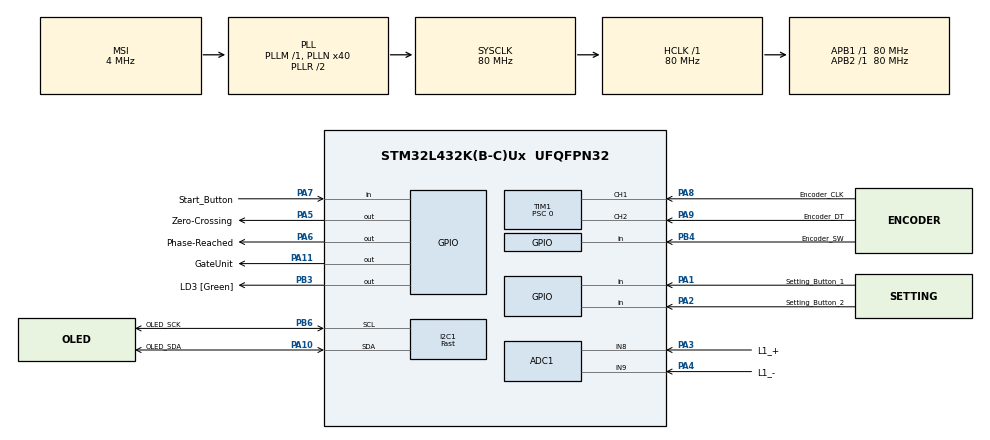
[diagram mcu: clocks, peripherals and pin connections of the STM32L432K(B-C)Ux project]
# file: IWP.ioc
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ADC1.Channel-1\#ChannelRegularConversion=ADC_CHANNEL_8
ADC1.NbrOfConversion=1
ADC1.NbrOfConversionFlag=1
ADC1.OffsetNumber-1\#ChannelRegularConversion=ADC_OFFSET_NONE
ADC1.Rank-1\#ChannelRegularConversion=1
ADC1.SamplingTime-1\#ChannelRegularConversion=ADC_SAMPLETIME_640CYCLES_5
ADC1.SingleDiff-1\#ChannelRegularConversion=ADC_DIFFERENTIAL_ENDED
ADC1.master=1
I2C1.I2C_Speed_Mode=I2C_Fast
I2C1.Timing=0x00702991
Mcu.Family=STM32L4
Mcu.Name=STM32L432K(B-C)Ux
Mcu.Package=UFQFPN32
NVIC.ADC1_IRQn=true\:0\:0\:false\:false\:true\:true\:true\:true
NVIC.PriorityGroup=NVIC_PRIORITYGROUP_4
NVIC.TIM2_IRQn=true\:0\:0\:false\:false\:true\:true\:true\:true
PA0.GPIO_Label=MCO [High speed clock in]
PA0.Mode=HSE-External-Clock-Source-for-LittleOrca
PA0.Signal=RCC_CK_IN
PA1.GPIO_Label=Setting_Button_1
PA1.GPIO_PuPd=GPIO_PULLDOWN
PA1.Signal=GPIO_Input
PA10.GPIO_Label=OLED_SDA
PA10.Mode=I2C
PA10.Signal=I2C1_SDA
PA11.GPIO_Label=GateUnit
PA11.Signal=GPIO_Output
PA13\ (JTMS-SWDIO).GPIO_Label=SWDIO
PA13\ (JTMS-SWDIO).Mode=Serial_Wire
PA13\ (JTMS-SWDIO).Signal=SYS_JTMS-SWDIO
PA14\ (JTCK-SWCLK).GPIO_Label=SWCLK
PA14\ (JTCK-SWCLK).Mode=Serial_Wire
PA14\ (JTCK-SWCLK).Signal=SYS_JTCK-SWCLK
PA2.GPIO_Label=Setting_Button_2
PA2.GPIO_PuPd=GPIO_PULLDOWN
PA2.Signal=GPIO_Input
PA3.GPIO_Label=L1_+
PA3.Signal=ADCx_IN8
PA4.GPIO_Label=L1_-
PA4.Signal=ADCx_IN9
PA5.GPIO_Label=Zero-Crossing
PA5.Signal=GPIO_Output
PA6.GPIO_Label=Phase-Reached
PA6.Signal=GPIO_Output
PA7.GPIO_Label=Start_Button
PA7.GPIO_PuPd=GPIO_PULLDOWN
PA7.Signal=GPIO_Input
PA8.GPIO_Label=Encoder_CLK
PA8.Signal=S_TIM1_CH1
PA9.GPIO_Label=Encoder_DT
PA9.Signal=S_TIM1_CH2
PB3\ (JTDO-TRACESWO).GPIO_Label=LD3 [Green]
PB3\ (JTDO-TRACESWO).Signal=GPIO_Output
PB4\ (NJTRST).GPIO_Label=Encoder_SW
PB4\ (NJTRST).GPIO_PuPd=GPIO_PULLDOWN
PB4\ (NJTRST).Signal=GPIO_Input
PB6.GPIO_Label=OLED_SCK
PB6.Mode=I2C
PB6.Signal=I2C1_SCL
PC14-OSC32_IN\ (PC14).Mode=LSE-External-Oscillator
PC14-OSC32_IN\ (PC14).Signal=RCC_OSC32_IN
PC15-OSC32_OUT\ (PC15).Mode=LSE-External-Oscillator
PC15-OSC32_OUT\ (PC15).Signal=RCC_OSC32_OUT
ProjectManager.HeapSize=0x200
ProjectManager.StackSize=0x400
ProjectManager.TargetToolchain=STM32CubeIDE
RCC.ADCFreq_Value=32000000
RCC.AHBFreq_Value=80000000
RCC.APB1Freq_Value=80000000
RCC.APB1TimFreq_Value=80000000
RCC.APB2Freq_Value=80000000
RCC.APB2TimFreq_Value=80000000
RCC.CortexFreq_Value=80000000
RCC.HCLKFreq_Value=80000000
RCC.HSE_VALUE=8000000
RCC.HSI16_VALUE=16000000
RCC.HSI48_VALUE=48000000
RCC.HSI_VALUE=16000000
RCC.MSI_VALUE=4000000
RCC.PLLMUL=RCC_PLLMUL_4
RCC.PLLN=40
RCC.PLLSAI1N=16
RCC.SYSCLKFreq_VALUE=80000000
RCC.SYSCLKSource=RCC_SYSCLKSOURCE_PLLCLK
RCC.USBFreq_Value=32000000
RCC.VCOOutputFreq_Value=160000000
SH.ADCx_IN8.0=ADC1_IN8,IN8-Differential
SH.ADCx_IN9.0=ADC1_IN9,IN8-Differential
SH.S_TIM1_CH1.0=TIM1_CH1,Encoder_Interface
SH.S_TIM1_CH2.0=TIM1_CH2,Encoder_Interface
TIM1.AutoReloadPreload=TIM_AUTORELOAD_PRELOAD_ENABLE
TIM1.EncoderMode=TIM_ENCODERMODE_TI12
TIM1.IC1Filter=10
TIM1.IC1Polarity=TIM_ICPOLARITY_FALLING
TIM1.IC2Filter=10
TIM1.IC2Polarity=TIM_ICPOLARITY_FALLING
TIM1.Period=65535
TIM1.Prescaler=0
TIM2.Channel-Output\ Compare1\ No\ Output=TIM_CHANNEL_1
TIM2.Period=2000 - 1
TIM2.Prescaler=20 - 1
TIM6.Prescaler=80 - 1
TIM6.TIM_MasterOutputTrigger=TIM_TRGO_RESET
VP_TIM2_VS_no_output1.Mode=Output Compare1 No Output
VP_TIM6_VS_ClockSourceINT.Mode=Enable_Timer
board=NUCLEO-L432KC

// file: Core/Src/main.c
/* USER CODE BEGIN Header */
/**
 ******************************************************************************
 * @file           : main.c
 * @brief          : Main program body
 ******************************************************************************
 * @attention
 *
 * Copyright (c) 2024 STMicroelectronics.
 * All rights reserved.
 *
 * This software is licensed under terms that can be found in the LICENSE file
 * in the root directory of this software component.
 * If no LICENSE file comes with this software, it is provided AS-IS.
 *
 ******************************************************************************
 */
/* USER CODE END Header */
#include "main.h"
#include "adc.h"
#include "i2c.h"
#include "tim.h"
#include "gpio.h"

/* USER CODE BEGIN Includes */
#include "PLL/PLL.h"
/* USER CODE END Includes */

void SystemClock_Config(void);

/* USER CODE BEGIN 0 */
extern void runTest();
/* USER CODE END 0 */

int main(void) {

	/* MCU Configuration--------------------------------------------------------*/

	/* Reset of all peripherals, Initializes the Flash interface and the Systick. */
	HAL_Init();

	/* USER CODE BEGIN Init */
	/* Initialize model */

	/* USER CODE END Init */

	/* Configure the system clock */
	SystemClock_Config();

	/* Initialize all configured peripherals */
	MX_GPIO_Init();
	MX_I2C1_Init();
	MX_TIM1_Init();
	MX_TIM2_Init();
	MX_ADC1_Init();
	MX_TIM6_Init();
	/* USER CODE BEGIN 2 */
	// Initializes the PLL
	PLL_initialize();

	// Starts the first ADC-Conversion
	HAL_ADC_Start_IT(&hadc1);

	// Starts the ISR for Timer 2
	HAL_TIM_Base_Start_IT(&htim2);

	// Starts the Timr 6 for the delay_us() function
	HAL_TIM_Base_Start(&htim6);

	// executes Tests for the Application
	runTest();

	/* USER CODE END 2 */

	/* Infinite loop */
	while (1) {

	}
}

void SystemClock_Config(void) {
	RCC_OscInitTypeDef RCC_OscInitStruct = { 0 };
	RCC_ClkInitTypeDef RCC_ClkInitStruct = { 0 };

	/** Configure the main internal regulator output voltage
	 */
	if (HAL_PWREx_ControlVoltageScaling(PWR_REGULATOR_VOLTAGE_SCALE1)
			!= HAL_OK) {
		Error_Handler();
	}

	/** Configure LSE Drive Capability
	 */
	HAL_PWR_EnableBkUpAccess();
	__HAL_RCC_LSEDRIVE_CONFIG(RCC_LSEDRIVE_LOW);

	/** Initializes the RCC Oscillators according to the specified parameters
	 * in the RCC_OscInitTypeDef structure.
	 */
	RCC_OscInitStruct.OscillatorType = RCC_OSCILLATORTYPE_LSE
			| RCC_OSCILLATORTYPE_MSI;
	RCC_OscInitStruct.LSEState = RCC_LSE_ON;
	RCC_OscInitStruct.MSIState = RCC_MSI_ON;
	RCC_OscInitStruct.MSICalibrationValue = 0;
	RCC_OscInitStruct.MSIClockRange = RCC_MSIRANGE_6;
	RCC_OscInitStruct.PLL.PLLState = RCC_PLL_ON;
	RCC_OscInitStruct.PLL.PLLSource = RCC_PLLSOURCE_MSI;
	RCC_OscInitStruct.PLL.PLLM = 1;
	RCC_OscInitStruct.PLL.PLLN = 40;
	RCC_OscInitStruct.PLL.PLLP = RCC_PLLP_DIV7;
	RCC_OscInitStruct.PLL.PLLQ = RCC_PLLQ_DIV2;
	RCC_OscInitStruct.PLL.PLLR = RCC_PLLR_DIV2;
	if (HAL_RCC_OscConfig(&RCC_OscInitStruct) != HAL_OK) {
		Error_Handler();
	}

	/** Initializes the CPU, AHB and APB buses clocks
	 */
	RCC_ClkInitStruct.ClockType = RCC_CLOCKTYPE_HCLK | RCC_CLOCKTYPE_SYSCLK
			| RCC_CLOCKTYPE_PCLK1 | RCC_CLOCKTYPE_PCLK2;
	RCC_ClkInitStruct.SYSCLKSource = RCC_SYSCLKSOURCE_PLLCLK;
	RCC_ClkInitStruct.AHBCLKDivider = RCC_SYSCLK_DIV1;
	RCC_ClkInitStruct.APB1CLKDivider = RCC_HCLK_DIV1;
	RCC_ClkInitStruct.APB2CLKDivider = RCC_HCLK_DIV1;

	if (HAL_RCC_ClockConfig(&RCC_ClkInitStruct, FLASH_LATENCY_4) != HAL_OK) {
		Error_Handler();
	}

	/** Enable MSI Auto calibration
	 */
	HAL_RCCEx_EnableMSIPLLMode();
}

void Error_Handler(void) {
	__disable_irq();
	while (1) {
	}
}
